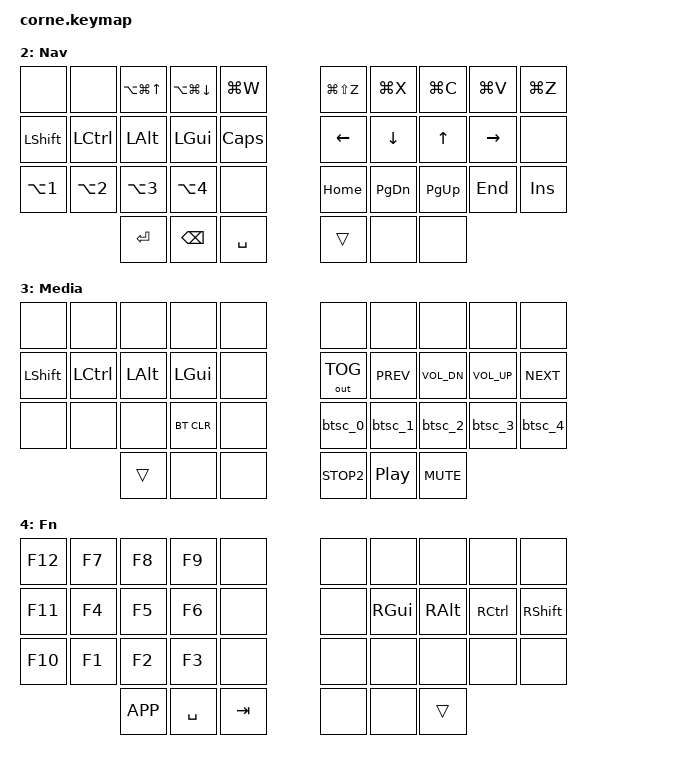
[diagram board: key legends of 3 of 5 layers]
#include <behaviors.dtsi>
#include <dt-bindings/zmk/keys.h>
#include <dt-bindings/zmk/bt.h>
#include <dt-bindings/zmk/outputs.h>

// layers
#define DEF     0
#define NUM     1
#define NAV     2
#define MEDIA   3
#define FUN     4

#include "keys/36.h"
#include "includes/macros.dtsi"
#include "includes/combos.dtsi"
#include "includes/behaviors.dtsi"

// ╰─────────┼─────────┼─────────┼─────────┼─────────┤   ├─────────┼─────────┼─────────┼─────────┼─────────╯
//                     │SEC THMB │PRM THMB │TER THMB │   │TER THMB │PRM THMB │SEC THMB │
//                     │   MED   │  NUM    │ LSHIFT  │   │  NAV    │CTRL+DEL │  FUN    │
//                     │ Sk SHFT │ REPEAT  │  SPACE  │   │  TAB    │  DEL    │ SK CTRL │
//                     ╰─────────────────────────────╯   ╰─────────────────────────────╯
//                          ╰caps_word on double tap, not sure if I like it yet

// Layer switching
#define SECLTHMB  &ltsk  MEDIA    LSHIFT  // tap for sticky shift : hold for media layer
#define PRMLTHMB  &ltr   NUM      0      //  zero here because key-repeat does not take arguments
#define TERLTHMB  &mt    LSHIFT   SPACE  //   tap for tab : hold for shift

#define TERRTHMB  &lt    NAV      TAB
#define PRMRTHMB  &kp    BSPC   // tap gives you backspace : long tap gives you delete word
#define SECRTHMB  &ltsk  FUN      RCTRL //  tap for sticky ctrl : hold for function layer

// shorter codes
#define BPSTE    &kp  LG(V)
#define BCPY     &kp  LG(C)
#define BCUT     &kp  LG(X)
#define BUNDO    &kp  LG(Z)
#define BREDO    &kp  LG(LS(Z))
#define BPREV    &kp  C_PREV
#define BNEXT    &kp  C_NEXT
#define BPLYPSE  &kp  C_PP
#define BMUTE    &kp  C_MUTE
#define BSTOP    &kp  K_STOP2
#define BVOLD    &kp  C_VOL_DN
#define BVOLU    &kp  C_VOL_UP
#define OUTTOG   &out OUT_TOG // toggle keyboard output bluetooth/usb
#define ___      &trans      //  transparent
#define _x_      &none
#define SPACE1   &kp  LA(N1)
#define SPACE2   &kp  LA(N2)
#define SPACE3   &kp  LA(N3)
#define SPACE4   &kp  LA(N4)

// Arc Browser 
#define NEXTAB   &kp  LA(LG(DOWN))
#define PREVTAB  &kp  LA(LG(UP))
#define CLOSETAB &kp  LG(W)

// Home row mods
#define HRML(k1, k2, k3, k4) &hml LSHFT k1 &hml LCTRL k2 &hml LALT  k3 &hml LGUI  k4
#define HRMR(k1, k2, k3, k4) &hmr RGUI  k1 &hmr RALT  k2 &hmr RCTRL k3 &hmr RSHFT k4

&mt {
    flavor = "tap-preferred";
    tapping_term_ms = <200>;
};

/ {
  chosen {
    zmk,matrix_transform = &five_column_transform;
  };
};

/ {
  keymap {
    compatible = "zmk,keymap";
    default_layer { // layer 0 (default)
      label = "Base";
      bindings = <
// ╭─────────────────────────────────────────────────╮   ╭─────────────────────────────────────────────────╮
// │    Q    │    W    │    E    │    R    │    T    │   │    Y    │    U    │    I    │    O    │    P    │
    &kp Q     &kp W     &kp E     &kp R     &kp T         &kp Y     &kp U     &kp I     &kp O     &kp P
// ├─────────┼─────────┼─────────┼─────────┼─────────┤   ├─────────┼─────────┼─────────┼─────────┼─────────┤
// │    A    │    S    │    D    │    F    │    G    │   │    H    │    J    │    K    │    L    │    '    │
    HRML(A,       S,        D,        F)    &kp G         &kp H     HRMR(J,       K,        L,       SQT)
// ├─────────┼─────────┼─────────┼─────────┼─────────┤   ├─────────┼─────────┼─────────┼─────────┼─────────┤
// │    Z    │    X    │    C    │    V    │    B    │   │    N    │    M    │   ,/;   │   ./:   │    /    │
    &kp Z     &kp X     &kp C     &kp V     &kp B         &kp N     &kp M     &cma_smi  &dot_cln  &kp FSLH
// ╰─────────┼─────────┼─────────┼─────────┼─────────┤   ├─────────┼─────────┼─────────┼─────────┼─────────╯
                        SECLTHMB  PRMLTHMB  TERLTHMB      TERRTHMB  PRMRTHMB  SECRTHMB
//                     ╰─────────────────────────────╯   ╰─────────────────────────────╯
      >;
    };
    number_layer { // layer 1 (numbers)
      label = "Num";
      bindings = <
// ╭─────────────────────────────────────────────────╮   ╭─────────────────────────────────────────────────╮
// │   NOP   │   NOP   │   NOP   │   NOP   │   NOP   │   │   NOP   │   NOP   │   NOP   │   NOP   │   NOP   │
    _x_       _x_       _x_       _x_       _x_           _x_       _x_       _x_       _x_       _x_
// ├─────────┼─────────┼─────────┼─────────┼─────────┤   ├─────────┼─────────┼─────────┼─────────┼─────────┤
// │    1    │    2    │    3    │    4    │    5    │   │     6   │    7    │    8    │    9    │    0    │
    HRML(N1,     N2,       N3,       N4)    &kp N5        &kp N6    HRMR(N7,     N8,       N9,       N0)
// ├─────────┼─────────┼─────────┼─────────┼─────────┤   ├─────────┼─────────┼─────────┼─────────┼─────────┤
// │   NOP   │   NOP   │   NOP   │   NOP   │   NOP   │   │   NOP   │   NOP   │   NOP   │   ./:   │   NOP   │
       _x_       _x_       _x_       _x_       _x_           _x_       _x_       _x_    &dot_cln     _x_
// ╰─────────┼─────────┼─────────┼─────────┼─────────┤   ├─────────┼─────────┼─────────┼─────────┼─────────╯
//                     │   NOP   │   NOP   │   NOP   │   │  SPACE  │   NOP   │  ENTER  │
                        _x_       ___       _x_           &kp SPACE &kp BSPC  &kp RET
//                     ╰─────────────────────────────╯   ╰─────────────────────────────╯
      >;
    };

    navigation_layer { // layer 2 (navigation)
      label = "Nav";
      bindings = <
// ╭─────────────────────────────────────────────────╮   ╭─────────────────────────────────────────────────╮
// │   NOP   │   NOP   │ PREVTAB │ NEXTTAB │ CLOSETAB│   │   REDO  │   CUT   │  COPY   │  PASTE  │  UNDO   │
    _x_       _x_       PREVTAB   NEXTAB    CLOSETAB      BREDO     BCUT      BCPY        BPSTE     BUNDO
// ├─────────┼─────────┼─────────┼─────────┼─────────┤   ├─────────┼─────────┼─────────┼─────────┼─────────┤
// │ SHIFT   │  CTRL   │   ALT   │   SUPER │   NOP   │   │  LEFT   │  DOWN   │    UP   │  RIGHT  │   NOP   │
    &kp LSHFT &kp LCTRL  &kp LALT &kp LGUI  &kp CAPS      &kp LEFT  &kp DOWN  &kp UP    &kp RIGHT _x_
// ├─────────┼─────────┼─────────┼─────────┼─────────┤   ├─────────┼─────────┼─────────┼─────────┼─────────┤
// │ SPACE1  │ SPACE2  │ SPACE3  │ SPACE4  │   NOP   │   │  HOME   │  PGDN   │   PGUP  │   END   │  INSERT │
    SPACE1    SPACE2    SPACE3    SPACE4    _x_           &kp HOME  &kp PG_DN &kp PG_UP  &kp END  &kp INS
// ╰─────────┼─────────┼─────────┼─────────┼─────────┤   ├─────────┼─────────┼─────────┼─────────┼─────────╯
//                     │  ENTER  │  BCKSPC │  SPACE  │   │   NOP   │   NOP   │   NOP   │
                        &kp RET   &kp BSPC  &kp SPACE     ___       _x_       _x_
//                     ╰─────────────────────────────╯   ╰─────────────────────────────╯
      >;
    };
    media_layer { // layer 5 (media)
      label = "Media";
      bindings = <
// ╭─────────────────────────────────────────────────╮   ╭─────────────────────────────────────────────────╮
// │   NOP   │   NOP   │   NOP   │   NOP   │   NOP   │   │   NOP   │   NOP   │   NOP   │   NOP   │   NOP   │
    _x_       _x_       _x_       _x_       _x_           _x_       _x_       _x_       _x_       _x_
// ├─────────┼─────────┼─────────┼─────────┼─────────┤   ├─────────┼─────────┼─────────┼─────────┼─────────┤
// │ SHIFT   │  CTRL   │   ALT   │   SUPER │   NOP   │   │   NOP   │PREV_TRCK│ VOl_DOWN│  VOL_UP │NEXT_TRCK│
    &kp LSHFT &kp LCTRL  &kp LALT &kp LGUI  _x_           OUTTOG    BPREV     BVOLD     BVOLU     BNEXT
// ├─────────┼─────────┼─────────┼─────────┼─────────┤   ├─────────┼─────────┼─────────┼─────────┼─────────┤
// │   NOP   │   NOP   │   NOP   │   NOP   │   NOP   │   │BTPROF 0 │BTPROF 1 │BTPROF 2 │BTPROF 3 │BTROF 4  │// shift to clear profile
    _x_       _x_       _x_       &bt BT_CLR _x_          &btsc_0   &btsc_1   &btsc_2   &btsc_3   &btsc_4
// ╰─────────┼─────────┼─────────┼─────────┼─────────┤   ├─────────┼─────────┼─────────┼─────────┼─────────╯
//                     │   NOP   │   NOP   │   NOP   │   │  STOP   │Pause/Ply│  MUTE   │
                        ___       _x_       _x_           BSTOP     BPLYPSE   BMUTE
//                     ╰─────────────────────────────╯   ╰─────────────────────────────╯
      >;
    };
    function_layer { // layer 6 (function)
      label = "Fn";
      bindings = <
// ╭─────────────────────────────────────────────────╮   ╭─────────────────────────────────────────────────╮
// │   F12   │   F7    │   F8    │   F9    │   NOP   │   │   NOP   │   NOP   │   NOP   │   NOP   │   NOP   │
    &kp F12   &kp F7    &kp F8    &kp F9    _x_           _x_       _x_       _x_       _x_       _x_
// ├─────────┼─────────┼─────────┼─────────┼─────────┤   ├─────────┼─────────┼─────────┼─────────┼─────────┤
// │   F11   │   F4    │   F5    │   F6    │   NOP   │   │   NOP   │  SUPER  │   ALT   │  CTRL   │  SHIFT  │
    &kp F11   &kp F4    &kp F5    &kp F6    _x_           _x_       &kp RGUI  &kp RALT  &kp RCTRL &kp RSHFT
// ├─────────┼─────────┼─────────┼─────────┼─────────┤   ├─────────┼─────────┼─────────┼─────────┼─────────┤
// │   F10   │   F1    │   F2    │   F3    │   NOP   │   │   NOP   │   NOP   │   NOP   │   NOP   │   NOP   │
    &kp F10   &kp F1    &kp F2    &kp F3    _x_           _x_       _x_       _x_       _x_       _x_
// ╰─────────┼─────────┼─────────┼─────────┼─────────┤   ├─────────┼─────────┼─────────┼─────────┼─────────╯
//                     │   APP   │  SPACE  │   TAB   │   │   NOP   │   NOP   │   NOP   │
                        &kp K_APP &kp SPACE &kp TAB       _x_       _x_       ___
//                     ╰─────────────────────────────╯   ╰─────────────────────────────╯
      >;
    };

  };
};

// vim:ft=cpp
